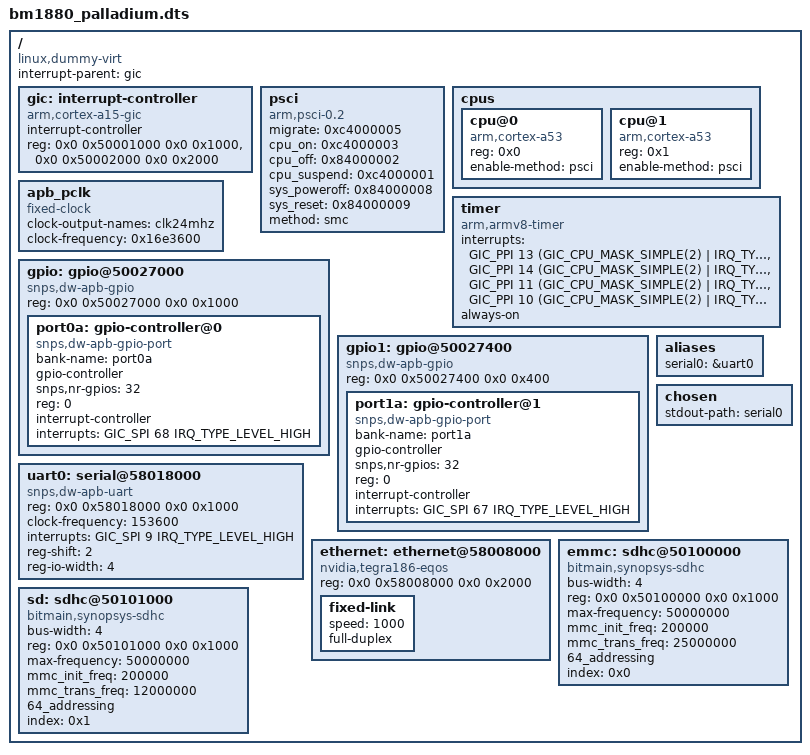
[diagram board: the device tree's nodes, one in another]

#include <dt-bindings/interrupt-controller/arm-gic.h>

/dts-v1/;

/memreserve/	0x0000000100000000 0x0000000000020000; // ATF BL31

/ {
	compatible = "linux,dummy-virt";
	#size-cells = <0x2>;
	#address-cells = <0x2>;
	interrupt-parent = <&gic>;

	gic: interrupt-controller {
		compatible = "arm,cortex-a15-gic";
		ranges;
		#size-cells = <0x2>;
		#address-cells = <0x2>;
		interrupt-controller;
		#interrupt-cells = <0x3>;
		reg = <0x0 0x50001000 0x0 0x1000>,
		      <0x0 0x50002000 0x0 0x2000>;
	};

	psci {
		migrate = <0xc4000005>;
		cpu_on = <0xc4000003>;
		cpu_off = <0x84000002>;
		cpu_suspend = <0xc4000001>;
		sys_poweroff = <0x84000008>;
		sys_reset = <0x84000009>;
		method = "smc";
		compatible = "arm,psci-0.2", "arm,psci";
	};

	cpus {
		#size-cells = <0x0>;
		#address-cells = <0x1>;

		cpu@0 {
			reg = <0x0>;
			enable-method = "psci";
			compatible = "arm,cortex-a53";
			device_type = "cpu";
		};

		cpu@1 {
			reg = <0x1>;
			enable-method = "psci";
			compatible = "arm,cortex-a53";
			device_type = "cpu";
		};
	};

	timer {
		interrupts = <GIC_PPI 13 (GIC_CPU_MASK_SIMPLE(2) | IRQ_TYPE_LEVEL_LOW)>,
			<GIC_PPI 14 (GIC_CPU_MASK_SIMPLE(2) | IRQ_TYPE_LEVEL_LOW)>,
			<GIC_PPI 11 (GIC_CPU_MASK_SIMPLE(2) | IRQ_TYPE_LEVEL_LOW)>,
			<GIC_PPI 10 (GIC_CPU_MASK_SIMPLE(2) | IRQ_TYPE_LEVEL_LOW)>;
		always-on;
		compatible = "arm,armv8-timer";
	};

	apb_pclk {
		phandle = <0x8000>;
		clock-output-names = "clk24mhz";
		clock-frequency = <0x16e3600>;
		#clock-cells = <0x0>;
		compatible = "fixed-clock";
	};

	gpio: gpio@50027000 {
		compatible = "snps,dw-apb-gpio";
		reg = <0x0 0x50027000 0x0 0x1000>;
		#address-cells = <1>;
		#size-cells = <0>;

		port0a: gpio-controller@0 {
			compatible = "snps,dw-apb-gpio-port";
			bank-name = "port0a";
			gpio-controller;
			#gpio-cells = <2>;
			snps,nr-gpios = <32>;
			reg = <0>;
			interrupt-controller;
			interrupts = <GIC_SPI 68 IRQ_TYPE_LEVEL_HIGH>;
		};
	};

	gpio1: gpio@50027400 {
		compatible = "snps,dw-apb-gpio";
		reg = <0x0 0x50027400 0x0 0x400>;
		#address-cells = <1>;
		#size-cells = <0>;

		port1a: gpio-controller@1 {
			compatible = "snps,dw-apb-gpio-port";
			bank-name = "port1a";
			gpio-controller;
			#gpio-cells = <2>;
			snps,nr-gpios = <32>;
			reg = <0>;
			interrupt-controller;
			interrupts = <GIC_SPI 67 IRQ_TYPE_LEVEL_HIGH>;
		};
	};

	uart0: serial@58018000 {
		compatible = "snps,dw-apb-uart";
		reg = <0x0 0x58018000 0x0 0x1000>;
		clock-frequency = <153600>;
		interrupts = <GIC_SPI 9 IRQ_TYPE_LEVEL_HIGH>;
		reg-shift = <2>;
		reg-io-width = <4>;
	};

	/* only support one ethernet in uboot */
#if 1
	ethernet: ethernet@58008000 {
		compatible = "nvidia,tegra186-eqos", "snps,dwc-qos-ethernet-4.10";
		reg = <0x0 0x58008000 0x0 0x2000>;
		reg-names = "mac";

		// fixed-phy for palladium, 1000M for RGMII
		fixed-link {
			speed = <1000>;
			full-duplex;
		};
	};
#else
	ethernet: ethernet@58028000 {
		compatible = "nvidia,tegra186-eqos", "snps,dwc-qos-ethernet-4.10";
		reg = <0x0 0x58028000 0x0 0x2000>;
		reg-names = "mac";

		// fixed-phy for palladium, 100M for RMII
		fixed-link {
			speed = <100>;
			full-duplex;
		};
	};
#endif

#if 0
	memory {
		reg = <0x1 0x00000000 0x0 0x40000000>;
		device_type = "memory";
	};
#endif
	aliases {
		serial0 = &uart0;
	};

	chosen {
		stdout-path = "serial0"; // "serial0:115200n8", no arguments means no re-initialization
	};

	emmc: sdhc@50100000 {
		compatible = "bitmain,synopsys-sdhc";
		bus-width = <4>;
		reg = <0x0 0x50100000 0x0 0x1000>;
		max-frequency = <50000000>;
		mmc_init_freq = <200000>;
		mmc_trans_freq = <25000000>;
		64_addressing;
		index = <0x0>;
		status = "okay";
	};

	sd: sdhc@50101000 {
		compatible = "bitmain,synopsys-sdhc";
		bus-width = <4>;
		reg = <0x0 0x50101000 0x0 0x1000>;
		max-frequency = <50000000>;
		mmc_init_freq = <200000>;
		mmc_trans_freq = <12000000>;
		64_addressing;
		index = <0x1>;
		status = "okay";
	};
};
